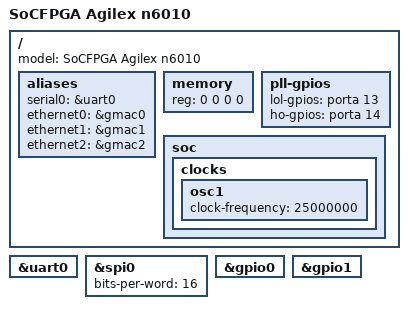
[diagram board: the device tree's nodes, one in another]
// SPDX-License-Identifier:     GPL-2.0
/*
 * Copyright (C) 2021, Intel Corporation
 */
#include "socfpga_agilex.dtsi"

/ {
	model = "SoCFPGA Agilex n6010";

	aliases {
		serial0 = &uart0;
		ethernet0 = &gmac0;
		ethernet1 = &gmac1;
		ethernet2 = &gmac2;
	};

	memory: memory {
		device_type = "memory";
		/* We expect the bootloader to fill in the reg */
		reg = <0 0 0 0>;
	};

	pll-gpios {
		lol-gpios = <&porta 13 GPIO_ACTIVE_HIGH>;
		ho-gpios = <&porta 14 GPIO_ACTIVE_HIGH>;
	};

	soc {
		clocks {
			osc1 {
				clock-frequency = <25000000>;
			};
		};
	};
};

&uart0 {
	status = "okay";
};

&spi0 {
	status = "okay";
	bits-per-word = <16>;
};

&gpio0 {
	status = "okay";
};

&gpio1 {
	status = "okay";
};
